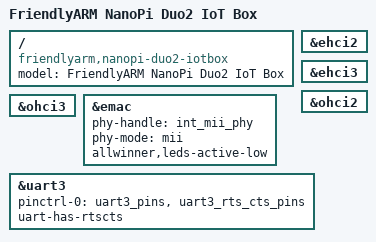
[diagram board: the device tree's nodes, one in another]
// SPDX-License-Identifier: (GPL-2.0+ OR MIT)
/*
 * Copyright (C) 2018 Karl Palsson <karlp@tweak.net.au>
 */

#include "sun8i-h3-nanopi-duo2.dts"

/ {
	model = "FriendlyARM NanoPi Duo2 IoT Box";
	compatible = "friendlyarm,nanopi-duo2-iotbox",
		"friendlyarm,nanopi-duo2",
		"allwinner,sun8i-h3";
};

&ehci2 {
	status = "okay";
};

&ehci3 {
	status = "okay";
};

&ohci2 {
	status = "okay";
};

&ohci3 {
	status = "okay";
};

&emac {
	phy-handle = <&int_mii_phy>;
	phy-mode = "mii";
	allwinner,leds-active-low;
	status = "okay";
};

/* Not addressed, SIM800C module on uart3 */
&uart3 {
	pinctrl-names = "default";
	pinctrl-0 = <&uart3_pins>, <&uart3_rts_cts_pins>;
	uart-has-rtscts;
	status = "okay";
};

